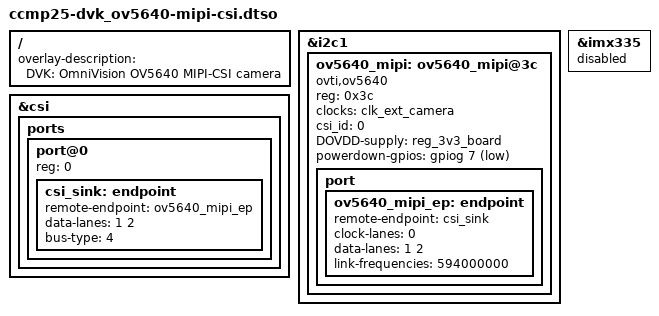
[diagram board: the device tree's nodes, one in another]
/*
 * Copyright 2025 Digi International Inc.
 *
 * Permission to use, copy, modify, and/or distribute this software for any
 * purpose with or without fee is hereby granted, provided that the above
 * copyright notice and this permission notice appear in all copies.
 * THE SOFTWARE IS PROVIDED "AS IS" AND THE AUTHOR DISCLAIMS ALL WARRANTIES
 * WITH REGARD TO THIS SOFTWARE INCLUDING ALL IMPLIED WARRANTIES OF
 * MERCHANTABILITY AND FITNESS. IN NO EVENT SHALL THE AUTHOR BE LIABLE FOR
 * ANY SPECIAL, DIRECT, INDIRECT, OR CONSEQUENTIAL DAMAGES OR ANY DAMAGES
 * WHATSOEVER RESULTING FROM LOSS OF USE, DATA OR PROFITS, WHETHER IN AN
 * ACTION OF CONTRACT, NEGLIGENCE OR OTHER TORTIOUS ACTION, ARISING OUT OF
 * OR IN CONNECTION WITH THE USE OR PERFORMANCE OF THIS SOFTWARE.
 */

#include <dt-bindings/gpio/gpio.h>

/dts-v1/;
/plugin/;

/ {
	fragment@0 {
		target-path = "/";
		__overlay__ {
			overlay-description = "DVK: OmniVision OV5640 MIPI-CSI camera";
		};
	};

	/* Add OmniVision OV5640 MIPI-CSI camera */
	fragment@1 {
		target = <&i2c1>;
		__overlay__ {
			#address-cells = <1>;
			#size-cells = <0>;

			/* MIPI-CSI camera */
			ov5640_mipi: ov5640_mipi@3c {
				compatible = "ovti,ov5640";
				reg = <0x3c>;
				clocks = <&clk_ext_camera>;
				clock-names = "xclk";
				csi_id = <0>;
				DOVDD-supply = <&reg_3v3_board>;
				powerdown-gpios = <&gpiog 7 (GPIO_ACTIVE_LOW | GPIO_PUSH_PULL)>; /* CSI_RESET */
				status = "okay";

				port {
					ov5640_mipi_ep: endpoint {
						remote-endpoint = <&csi_sink>;
						clock-lanes = <0>;
						data-lanes = <1 2>;
						link-frequencies = /bits/ 64 <594000000>;
					};
				};
			};
		};
	};

	/* Set CSI endpoint */
	fragment@2 {
		target = <&csi>;
		__overlay__ {
			ports {
				#address-cells = <1>;
				#size-cells = <0>;
				port@0 {
					reg = <0>;
					csi_sink: endpoint {
						remote-endpoint = <&ov5640_mipi_ep>;
						data-lanes = <1 2>;
						bus-type = <4>;
					};
				};
			};
		};
	};

	/* Disable Sony imx335 MIPI-CSI camera */
	fragment@3 {
		target = <&imx335>;
		__overlay__ {
			status = "disabled";
		};
	};

};
